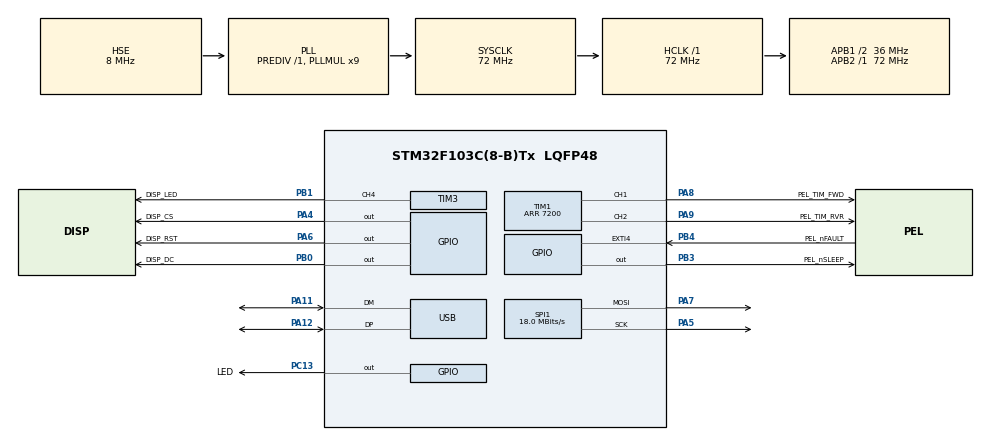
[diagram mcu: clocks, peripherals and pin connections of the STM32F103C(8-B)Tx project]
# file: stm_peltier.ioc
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Dma.Request0=SPI1_TX
Dma.SPI1_TX.0.Direction=DMA_MEMORY_TO_PERIPH
Dma.SPI1_TX.0.Instance=DMA1_Channel3
Dma.SPI1_TX.0.MemDataAlignment=DMA_MDATAALIGN_BYTE
Dma.SPI1_TX.0.MemInc=DMA_MINC_ENABLE
Dma.SPI1_TX.0.Mode=DMA_NORMAL
Dma.SPI1_TX.0.PeriphDataAlignment=DMA_PDATAALIGN_BYTE
Dma.SPI1_TX.0.PeriphInc=DMA_PINC_DISABLE
Dma.SPI1_TX.0.Priority=DMA_PRIORITY_LOW
Mcu.Family=STM32F1
Mcu.Name=STM32F103C(8-B)Tx
Mcu.Package=LQFP48
NVIC.DMA1_Channel3_IRQn=true\:0\:0\:false\:false\:true\:false\:true\:true
NVIC.EXTI4_IRQn=true\:0\:0\:false\:false\:true\:true\:true\:true
NVIC.PriorityGroup=NVIC_PRIORITYGROUP_4
NVIC.USB_LP_CAN1_RX0_IRQn=true\:0\:0\:false\:false\:true\:false\:true\:true
PA11.Mode=Device
PA11.Signal=USB_DM
PA12.Mode=Device
PA12.Signal=USB_DP
PA13.Mode=Serial_Wire
PA13.Signal=SYS_JTMS-SWDIO
PA14.Mode=Serial_Wire
PA14.Signal=SYS_JTCK-SWCLK
PA4.GPIO_Label=DISP_CS
PA4.Signal=GPIO_Output
PA5.Mode=TX_Only_Simplex_Unidirect_Master
PA5.Signal=SPI1_SCK
PA6.GPIO_Label=DISP_RST
PA6.Signal=GPIO_Output
PA7.Mode=TX_Only_Simplex_Unidirect_Master
PA7.Signal=SPI1_MOSI
PA8.GPIO_Label=PEL_TIM_FWD
PA8.Signal=S_TIM1_CH1
PA9.GPIO_Label=PEL_TIM_RVR
PA9.Signal=S_TIM1_CH2
PB0.GPIO_Label=DISP_DC
PB0.Signal=GPIO_Output
PB1.GPIO_Label=DISP_LED
PB1.Signal=S_TIM3_CH4
PB3.GPIO_Label=PEL_nSLEEP
PB3.Signal=GPIO_Output
PB4.GPIO_Label=PEL_nFAULT
PB4.GPIO_ModeDefaultEXTI=GPIO_MODE_IT_FALLING
PB4.GPIO_PuPd=GPIO_PULLUP
PB4.Signal=GPXTI4
PC13-TAMPER-RTC.GPIO_Label=LED
PC13-TAMPER-RTC.Signal=GPIO_Output
PC14-OSC32_IN.Mode=LSE-External-Oscillator
PC14-OSC32_IN.Signal=RCC_OSC32_IN
PC15-OSC32_OUT.Mode=LSE-External-Oscillator
PC15-OSC32_OUT.Signal=RCC_OSC32_OUT
PD0-OSC_IN.Mode=HSE-External-Oscillator
PD0-OSC_IN.Signal=RCC_OSC_IN
PD1-OSC_OUT.Mode=HSE-External-Oscillator
PD1-OSC_OUT.Signal=RCC_OSC_OUT
ProjectManager.HeapSize=0x200
ProjectManager.StackSize=0x400
ProjectManager.TargetToolchain=STM32CubeIDE
RCC.AHBFreq_Value=72000000
RCC.APB1CLKDivider=RCC_HCLK_DIV2
RCC.APB1Freq_Value=36000000
RCC.APB1TimFreq_Value=72000000
RCC.APB2Freq_Value=72000000
RCC.APB2TimFreq_Value=72000000
RCC.HCLKFreq_Value=72000000
RCC.PLLMUL=RCC_PLL_MUL9
RCC.PLLSourceVirtual=RCC_PLLSOURCE_HSE
RCC.SYSCLKFreq_VALUE=72000000
RCC.SYSCLKSource=RCC_SYSCLKSOURCE_PLLCLK
RCC.USBFreq_Value=48000000
RCC.USBPrescaler=RCC_USBCLKSOURCE_PLL_DIV1_5
SH.S_TIM1_CH1.0=TIM1_CH1,PWM Generation1 CH1
SH.S_TIM1_CH2.0=TIM1_CH2,PWM Generation2 CH2
SH.S_TIM3_CH4.0=TIM3_CH4,PWM Generation4 CH4
SPI1.BaudRatePrescaler=SPI_BAUDRATEPRESCALER_4
SPI1.CLKPhase=SPI_PHASE_1EDGE
SPI1.CLKPolarity=SPI_POLARITY_HIGH
SPI1.CalculateBaudRate=18.0 MBits/s
SPI1.Direction=SPI_DIRECTION_2LINES
SPI1.Mode=SPI_MODE_MASTER
SPI1.VirtualType=VM_MASTER
TIM1.Channel-PWM\ Generation1\ CH1=TIM_CHANNEL_1
TIM1.Channel-PWM\ Generation2\ CH2=TIM_CHANNEL_2
TIM1.Period=7200
TIM3.Channel-PWM\ Generation4\ CH4=TIM_CHANNEL_4
TIM3.Period=7200
USB_DEVICE.APP_RX_DATA_SIZE=64
USB_DEVICE.APP_TX_DATA_SIZE=64
USB_DEVICE.CLASS_NAME_FS=CDC
USB_DEVICE.VirtualMode=Cdc
USB_DEVICE.VirtualModeFS=Cdc_FS
VP_TIM1_VS_ClockSourceINT.Mode=Internal
VP_TIM3_VS_ClockSourceINT.Mode=Internal
VP_USB_DEVICE_VS_USB_DEVICE_CDC_FS.Mode=CDC_FS
board=custom

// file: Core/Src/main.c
/* USER CODE BEGIN Header */
/**
  ******************************************************************************
  * @file           : main.c
  * @brief          : Main program body
  ******************************************************************************
  * @attention
  *
  * Copyright (c) 2025 STMicroelectronics.
  * All rights reserved.
  *
  * This software is licensed under terms that can be found in the LICENSE file
  * in the root directory of this software component.
  * If no LICENSE file comes with this software, it is provided AS-IS.
  *
  ******************************************************************************
  */
/* USER CODE END Header */
#include <DRV8833.h>
#include "main.h"
#include "usb_device.h"

/* USER CODE BEGIN Includes */
#include "st7789.h"
/* USER CODE END Includes */

SPI_HandleTypeDef hspi1;
DMA_HandleTypeDef hdma_spi1_tx;

TIM_HandleTypeDef htim1;
TIM_HandleTypeDef htim3;

/* USER CODE BEGIN PV  */
uint8_t err_fl = 0;
/* USER CODE END PV */

void SystemClock_Config(void);
static void MX_GPIO_Init(void);
static void MX_DMA_Init(void);
static void MX_SPI1_Init(void);
static void MX_TIM1_Init(void);
static void MX_TIM3_Init(void);

/* USER CODE BEGIN 0 */
void _setBackLight(uint8_t percent)
{
	uint32_t val = (uint32_t)percent*TIM3->ARR/100;
	__HAL_TIM_SET_COMPARE(&htim3,TIM_CHANNEL_4,val);
}
/* USER CODE END 0 */

int main(void)
{

  /* MCU Configuration--------------------------------------------------------*/

  /* Reset of all peripherals, Initializes the Flash interface and the Systick. */
  HAL_Init();

  /* Configure the system clock */
  SystemClock_Config();

  /* Initialize all configured peripherals */
  MX_GPIO_Init();
  MX_DMA_Init();
  MX_SPI1_Init();
  MX_TIM1_Init();
  MX_TIM3_Init();
  MX_USB_DEVICE_Init();
  /* USER CODE BEGIN 2 */
  HAL_TIM_PWM_Start(&htim3, TIM_CHANNEL_4);
  _setBackLight(50);
  ST7789_Init();
  //ST7789_Test();
  /* USER CODE END 2 */

  /* Infinite loop */
  /* USER CODE BEGIN WHILE */
  while (1)
  {
	  _PELTIER_HEAT();
	  HAL_Delay(1000);
	  _PELTIER_COOL();
	  HAL_Delay(1000);
	  _PELTIER_STOP();
	  HAL_Delay(1000);
    /* USER CODE END WHILE */

  }
}

void SystemClock_Config(void)
{
  RCC_OscInitTypeDef RCC_OscInitStruct = {0};
  RCC_ClkInitTypeDef RCC_ClkInitStruct = {0};
  RCC_PeriphCLKInitTypeDef PeriphClkInit = {0};

  /** Initializes the RCC Oscillators according to the specified parameters
  * in the RCC_OscInitTypeDef structure.
  */
  RCC_OscInitStruct.OscillatorType = RCC_OSCILLATORTYPE_HSE;
  RCC_OscInitStruct.HSEState = RCC_HSE_ON;
  RCC_OscInitStruct.HSEPredivValue = RCC_HSE_PREDIV_DIV1;
  RCC_OscInitStruct.HSIState = RCC_HSI_ON;
  RCC_OscInitStruct.PLL.PLLState = RCC_PLL_ON;
  RCC_OscInitStruct.PLL.PLLSource = RCC_PLLSOURCE_HSE;
  RCC_OscInitStruct.PLL.PLLMUL = RCC_PLL_MUL9;
  if (HAL_RCC_OscConfig(&RCC_OscInitStruct) != HAL_OK)
  {
    Error_Handler();
  }

  /** Initializes the CPU, AHB and APB buses clocks
  */
  RCC_ClkInitStruct.ClockType = RCC_CLOCKTYPE_HCLK|RCC_CLOCKTYPE_SYSCLK
                              |RCC_CLOCKTYPE_PCLK1|RCC_CLOCKTYPE_PCLK2;
  RCC_ClkInitStruct.SYSCLKSource = RCC_SYSCLKSOURCE_PLLCLK;
  RCC_ClkInitStruct.AHBCLKDivider = RCC_SYSCLK_DIV1;
  RCC_ClkInitStruct.APB1CLKDivider = RCC_HCLK_DIV2;
  RCC_ClkInitStruct.APB2CLKDivider = RCC_HCLK_DIV1;

  if (HAL_RCC_ClockConfig(&RCC_ClkInitStruct, FLASH_LATENCY_2) != HAL_OK)
  {
    Error_Handler();
  }
  PeriphClkInit.PeriphClockSelection = RCC_PERIPHCLK_USB;
  PeriphClkInit.UsbClockSelection = RCC_USBCLKSOURCE_PLL_DIV1_5;
  if (HAL_RCCEx_PeriphCLKConfig(&PeriphClkInit) != HAL_OK)
  {
    Error_Handler();
  }
}

static void MX_SPI1_Init(void)
{

  /* SPI1 parameter configuration*/
  hspi1.Instance = SPI1;
  hspi1.Init.Mode = SPI_MODE_MASTER;
  hspi1.Init.Direction = SPI_DIRECTION_2LINES;
  hspi1.Init.DataSize = SPI_DATASIZE_8BIT;
  hspi1.Init.CLKPolarity = SPI_POLARITY_HIGH;
  hspi1.Init.CLKPhase = SPI_PHASE_1EDGE;
  hspi1.Init.NSS = SPI_NSS_SOFT;
  hspi1.Init.BaudRatePrescaler = SPI_BAUDRATEPRESCALER_4;
  hspi1.Init.FirstBit = SPI_FIRSTBIT_MSB;
  hspi1.Init.TIMode = SPI_TIMODE_DISABLE;
  hspi1.Init.CRCCalculation = SPI_CRCCALCULATION_DISABLE;
  hspi1.Init.CRCPolynomial = 10;
  if (HAL_SPI_Init(&hspi1) != HAL_OK)
  {
    Error_Handler();
  }

}

static void MX_TIM1_Init(void)
{

  TIM_ClockConfigTypeDef sClockSourceConfig = {0};
  TIM_MasterConfigTypeDef sMasterConfig = {0};
  TIM_OC_InitTypeDef sConfigOC = {0};
  TIM_BreakDeadTimeConfigTypeDef sBreakDeadTimeConfig = {0};

  htim1.Instance = TIM1;
  htim1.Init.Prescaler = 0;
  htim1.Init.CounterMode = TIM_COUNTERMODE_UP;
  htim1.Init.Period = 7200;
  htim1.Init.ClockDivision = TIM_CLOCKDIVISION_DIV1;
  htim1.Init.RepetitionCounter = 0;
  htim1.Init.AutoReloadPreload = TIM_AUTORELOAD_PRELOAD_DISABLE;
  if (HAL_TIM_Base_Init(&htim1) != HAL_OK)
  {
    Error_Handler();
  }
  sClockSourceConfig.ClockSource = TIM_CLOCKSOURCE_INTERNAL;
  if (HAL_TIM_ConfigClockSource(&htim1, &sClockSourceConfig) != HAL_OK)
  {
    Error_Handler();
  }
  if (HAL_TIM_PWM_Init(&htim1) != HAL_OK)
  {
    Error_Handler();
  }
  sMasterConfig.MasterOutputTrigger = TIM_TRGO_RESET;
  sMasterConfig.MasterSlaveMode = TIM_MASTERSLAVEMODE_DISABLE;
  if (HAL_TIMEx_MasterConfigSynchronization(&htim1, &sMasterConfig) != HAL_OK)
  {
    Error_Handler();
  }
  sConfigOC.OCMode = TIM_OCMODE_PWM1;
  sConfigOC.Pulse = 0;
  sConfigOC.OCPolarity = TIM_OCPOLARITY_HIGH;
  sConfigOC.OCNPolarity = TIM_OCNPOLARITY_HIGH;
  sConfigOC.OCFastMode = TIM_OCFAST_DISABLE;
  sConfigOC.OCIdleState = TIM_OCIDLESTATE_RESET;
  sConfigOC.OCNIdleState = TIM_OCNIDLESTATE_RESET;
  if (HAL_TIM_PWM_ConfigChannel(&htim1, &sConfigOC, TIM_CHANNEL_1) != HAL_OK)
  {
    Error_Handler();
  }
  if (HAL_TIM_PWM_ConfigChannel(&htim1, &sConfigOC, TIM_CHANNEL_2) != HAL_OK)
  {
    Error_Handler();
  }
  sBreakDeadTimeConfig.OffStateRunMode = TIM_OSSR_DISABLE;
  sBreakDeadTimeConfig.OffStateIDLEMode = TIM_OSSI_DISABLE;
  sBreakDeadTimeConfig.LockLevel = TIM_LOCKLEVEL_OFF;
  sBreakDeadTimeConfig.DeadTime = 0;
  sBreakDeadTimeConfig.BreakState = TIM_BREAK_DISABLE;
  sBreakDeadTimeConfig.BreakPolarity = TIM_BREAKPOLARITY_HIGH;
  sBreakDeadTimeConfig.AutomaticOutput = TIM_AUTOMATICOUTPUT_DISABLE;
  if (HAL_TIMEx_ConfigBreakDeadTime(&htim1, &sBreakDeadTimeConfig) != HAL_OK)
  {
    Error_Handler();
  }
  HAL_TIM_MspPostInit(&htim1);

}

static void MX_TIM3_Init(void)
{

  TIM_ClockConfigTypeDef sClockSourceConfig = {0};
  TIM_MasterConfigTypeDef sMasterConfig = {0};
  TIM_OC_InitTypeDef sConfigOC = {0};

  htim3.Instance = TIM3;
  htim3.Init.Prescaler = 0;
  htim3.Init.CounterMode = TIM_COUNTERMODE_UP;
  htim3.Init.Period = 7200;
  htim3.Init.ClockDivision = TIM_CLOCKDIVISION_DIV1;
  htim3.Init.AutoReloadPreload = TIM_AUTORELOAD_PRELOAD_DISABLE;
  if (HAL_TIM_Base_Init(&htim3) != HAL_OK)
  {
    Error_Handler();
  }
  sClockSourceConfig.ClockSource = TIM_CLOCKSOURCE_INTERNAL;
  if (HAL_TIM_ConfigClockSource(&htim3, &sClockSourceConfig) != HAL_OK)
  {
    Error_Handler();
  }
  if (HAL_TIM_PWM_Init(&htim3) != HAL_OK)
  {
    Error_Handler();
  }
  sMasterConfig.MasterOutputTrigger = TIM_TRGO_RESET;
  sMasterConfig.MasterSlaveMode = TIM_MASTERSLAVEMODE_DISABLE;
  if (HAL_TIMEx_MasterConfigSynchronization(&htim3, &sMasterConfig) != HAL_OK)
  {
    Error_Handler();
  }
  sConfigOC.OCMode = TIM_OCMODE_PWM1;
  sConfigOC.Pulse = 0;
  sConfigOC.OCPolarity = TIM_OCPOLARITY_HIGH;
  sConfigOC.OCFastMode = TIM_OCFAST_DISABLE;
  if (HAL_TIM_PWM_ConfigChannel(&htim3, &sConfigOC, TIM_CHANNEL_4) != HAL_OK)
  {
    Error_Handler();
  }
  HAL_TIM_MspPostInit(&htim3);

}

static void MX_DMA_Init(void)
{

  /* DMA controller clock enable */
  __HAL_RCC_DMA1_CLK_ENABLE();

  /* DMA interrupt init */
  /* DMA1_Channel3_IRQn interrupt configuration */
  HAL_NVIC_SetPriority(DMA1_Channel3_IRQn, 0, 0);
  HAL_NVIC_EnableIRQ(DMA1_Channel3_IRQn);

}

static void MX_GPIO_Init(void)
{
  GPIO_InitTypeDef GPIO_InitStruct = {0};

  /* GPIO Ports Clock Enable */
  __HAL_RCC_GPIOC_CLK_ENABLE();
  __HAL_RCC_GPIOD_CLK_ENABLE();
  __HAL_RCC_GPIOA_CLK_ENABLE();
  __HAL_RCC_GPIOB_CLK_ENABLE();

  /*Configure GPIO pin Output Level */
  HAL_GPIO_WritePin(LED_GPIO_Port, LED_Pin, GPIO_PIN_RESET);

  /*Configure GPIO pin Output Level */
  HAL_GPIO_WritePin(GPIOA, DISP_CS_Pin|DISP_RST_Pin, GPIO_PIN_RESET);

  /*Configure GPIO pin Output Level */
  HAL_GPIO_WritePin(GPIOB, DISP_DC_Pin|PEL_nSLEEP_Pin, GPIO_PIN_RESET);

  /*Configure GPIO pin : LED_Pin */
  GPIO_InitStruct.Pin = LED_Pin;
  GPIO_InitStruct.Mode = GPIO_MODE_OUTPUT_PP;
  GPIO_InitStruct.Pull = GPIO_NOPULL;
  GPIO_InitStruct.Speed = GPIO_SPEED_FREQ_LOW;
  HAL_GPIO_Init(LED_GPIO_Port, &GPIO_InitStruct);

  /*Configure GPIO pins : DISP_CS_Pin DISP_RST_Pin */
  GPIO_InitStruct.Pin = DISP_CS_Pin|DISP_RST_Pin;
  GPIO_InitStruct.Mode = GPIO_MODE_OUTPUT_PP;
  GPIO_InitStruct.Pull = GPIO_NOPULL;
  GPIO_InitStruct.Speed = GPIO_SPEED_FREQ_LOW;
  HAL_GPIO_Init(GPIOA, &GPIO_InitStruct);

  /*Configure GPIO pins : DISP_DC_Pin PEL_nSLEEP_Pin */
  GPIO_InitStruct.Pin = DISP_DC_Pin|PEL_nSLEEP_Pin;
  GPIO_InitStruct.Mode = GPIO_MODE_OUTPUT_PP;
  GPIO_InitStruct.Pull = GPIO_NOPULL;
  GPIO_InitStruct.Speed = GPIO_SPEED_FREQ_LOW;
  HAL_GPIO_Init(GPIOB, &GPIO_InitStruct);

  /*Configure GPIO pin : PEL_nFAULT_Pin */
  GPIO_InitStruct.Pin = PEL_nFAULT_Pin;
  GPIO_InitStruct.Mode = GPIO_MODE_IT_FALLING;
  GPIO_InitStruct.Pull = GPIO_PULLUP;
  HAL_GPIO_Init(PEL_nFAULT_GPIO_Port, &GPIO_InitStruct);

  /* EXTI interrupt init*/
  HAL_NVIC_SetPriority(EXTI4_IRQn, 0, 0);
  HAL_NVIC_EnableIRQ(EXTI4_IRQn);

}

void Error_Handler(void)
{
  __disable_irq();
  while (1)
  {
  }
}
